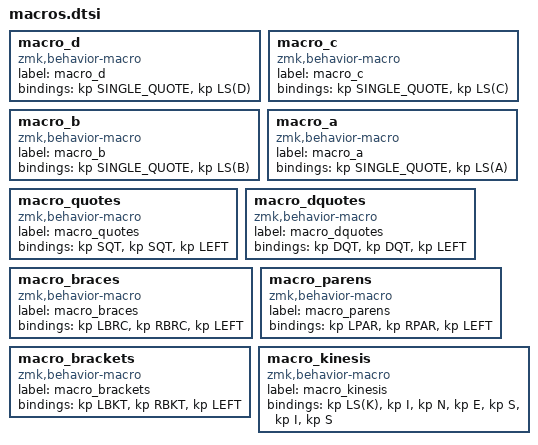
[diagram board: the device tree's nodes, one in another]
macro_d: macro_d{
compatible = "zmk,behavior-macro";
label = "macro_d";
#binding-cells = <0>;
bindings = <&kp SINGLE_QUOTE>, <&kp LS(D)>;
};
macro_c: macro_c{
compatible = "zmk,behavior-macro";
label = "macro_c";
#binding-cells = <0>;
bindings = <&kp SINGLE_QUOTE>, <&kp LS(C)>;
};
macro_b: macro_b{
compatible = "zmk,behavior-macro";
label = "macro_b";
#binding-cells = <0>;
bindings = <&kp SINGLE_QUOTE>, <&kp LS(B)>;
};
macro_a: macro_a{
compatible = "zmk,behavior-macro";
label = "macro_a";
#binding-cells = <0>;
bindings = <&kp SINGLE_QUOTE>, <&kp LS(A)>;
};
macro_quotes: macro_quotes{
compatible = "zmk,behavior-macro";
label = "macro_quotes";
#binding-cells = <0>;
bindings = <&kp SQT>, <&kp SQT>, <&kp LEFT>;
};
macro_dquotes: macro_dquotes{
compatible = "zmk,behavior-macro";
label = "macro_dquotes";
#binding-cells = <0>;
bindings = <&kp DQT>, <&kp DQT>, <&kp LEFT>;
};
macro_braces: macro_braces{
compatible = "zmk,behavior-macro";
label = "macro_braces";
#binding-cells = <0>;
bindings = <&kp LBRC>, <&kp RBRC>, <&kp LEFT>;
};
macro_parens: macro_parens{
compatible = "zmk,behavior-macro";
label = "macro_parens";
#binding-cells = <0>;
bindings = <&kp LPAR>, <&kp RPAR>, <&kp LEFT>;
};
macro_brackets: macro_brackets{
compatible = "zmk,behavior-macro";
label = "macro_brackets";
#binding-cells = <0>;
bindings = <&kp LBKT>, <&kp RBKT>, <&kp LEFT>;
};
macro_kinesis: macro_kinesis{
compatible = "zmk,behavior-macro";
label = "macro_kinesis";
#binding-cells = <0>;
bindings = <&kp LS(K)>, <&kp I>, <&kp N>, <&kp E>, <&kp S>, <&kp I>, <&kp S>;
};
